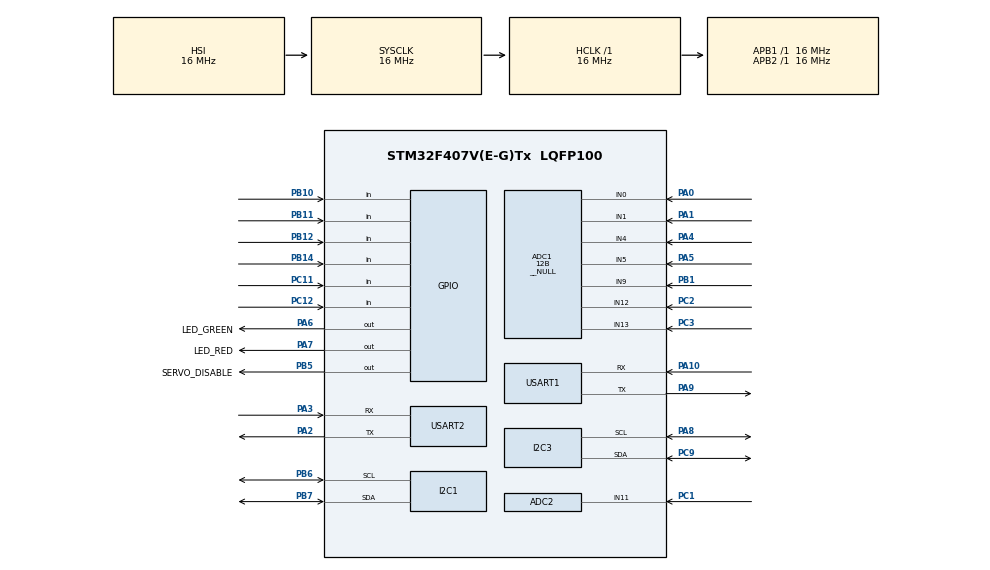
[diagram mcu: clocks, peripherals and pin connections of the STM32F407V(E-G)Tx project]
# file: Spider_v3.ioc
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ADC1.Channel-0\#ChannelRegularConversion=ADC_CHANNEL_13
ADC1.Channel-1\#ChannelRegularConversion=ADC_CHANNEL_12
ADC1.Channel-10\#ChannelRegularConversion=ADC_CHANNEL_9
ADC1.Channel-2\#ChannelRegularConversion=ADC_CHANNEL_1
ADC1.Channel-3\#ChannelRegularConversion=ADC_CHANNEL_0
ADC1.Channel-4\#ChannelRegularConversion=ADC_CHANNEL_0
ADC1.Channel-5\#ChannelRegularConversion=ADC_CHANNEL_0
ADC1.Channel-6\#ChannelRegularConversion=ADC_CHANNEL_0
ADC1.Channel-7\#ChannelRegularConversion=ADC_CHANNEL_0
ADC1.Channel-8\#ChannelRegularConversion=ADC_CHANNEL_5
ADC1.Channel-9\#ChannelRegularConversion=ADC_CHANNEL_4
ADC1.ClockPrescaler=ADC_CLOCK_SYNC_PCLK_DIV6
ADC1.ContinuousConvMode=ENABLE
ADC1.DMAContinuousRequests=ENABLE
ADC1.DataAlign=ADC_DATAALIGN_RIGHT
ADC1.DiscontinuousConvMode=DISABLE
ADC1.EOCSelection=ADC_EOC_SINGLE_CONV
ADC1.EnableAnalogWatchDog=false
ADC1.ExternalTrigConv=ADC_SOFTWARE_START
ADC1.ExternalTrigConvEdge=ADC_EXTERNALTRIGCONVEDGE_NONE
ADC1.InjNumberOfConversion=0
ADC1.Mode=__NULL
ADC1.NbrOfConversion=7
ADC1.NbrOfConversionFlag=1
ADC1.Rank-0\#ChannelRegularConversion=1
ADC1.Rank-1\#ChannelRegularConversion=2
ADC1.Rank-10\#ChannelRegularConversion=7
ADC1.Rank-2\#ChannelRegularConversion=3
ADC1.Rank-3\#ChannelRegularConversion=4
ADC1.Rank-4\#ChannelRegularConversion=5
ADC1.Rank-5\#ChannelRegularConversion=6
ADC1.Rank-6\#ChannelRegularConversion=7
ADC1.Rank-7\#ChannelRegularConversion=8
ADC1.Rank-8\#ChannelRegularConversion=5
ADC1.Rank-9\#ChannelRegularConversion=6
ADC1.Resolution=ADC_RESOLUTION_12B
ADC1.SamplingTime-0\#ChannelRegularConversion=ADC_SAMPLETIME_480CYCLES
ADC1.SamplingTime-1\#ChannelRegularConversion=ADC_SAMPLETIME_480CYCLES
ADC1.SamplingTime-10\#ChannelRegularConversion=ADC_SAMPLETIME_480CYCLES
ADC1.SamplingTime-2\#ChannelRegularConversion=ADC_SAMPLETIME_480CYCLES
ADC1.SamplingTime-3\#ChannelRegularConversion=ADC_SAMPLETIME_480CYCLES
ADC1.SamplingTime-4\#ChannelRegularConversion=ADC_SAMPLETIME_3CYCLES
ADC1.SamplingTime-5\#ChannelRegularConversion=ADC_SAMPLETIME_3CYCLES
ADC1.SamplingTime-6\#ChannelRegularConversion=ADC_SAMPLETIME_3CYCLES
ADC1.SamplingTime-7\#ChannelRegularConversion=ADC_SAMPLETIME_3CYCLES
ADC1.SamplingTime-8\#ChannelRegularConversion=ADC_SAMPLETIME_480CYCLES
ADC1.SamplingTime-9\#ChannelRegularConversion=ADC_SAMPLETIME_480CYCLES
ADC1.ScanConvMode=ENABLE
ADC1.master=1
ADC2.Channel-0\#ChannelRegularConversion=ADC_CHANNEL_11
ADC2.ClockPrescaler=ADC_CLOCK_SYNC_PCLK_DIV6
ADC2.NbrOfConversionFlag=1
ADC2.Rank-0\#ChannelRegularConversion=1
ADC2.SamplingTime-0\#ChannelRegularConversion=ADC_SAMPLETIME_28CYCLES
Dma.ADC1.0.Direction=DMA_PERIPH_TO_MEMORY
Dma.ADC1.0.FIFOMode=DMA_FIFOMODE_DISABLE
Dma.ADC1.0.Instance=DMA2_Stream0
Dma.ADC1.0.MemDataAlignment=DMA_MDATAALIGN_HALFWORD
Dma.ADC1.0.MemInc=DMA_MINC_ENABLE
Dma.ADC1.0.Mode=DMA_CIRCULAR
Dma.ADC1.0.PeriphDataAlignment=DMA_PDATAALIGN_HALFWORD
Dma.ADC1.0.PeriphInc=DMA_PINC_DISABLE
Dma.ADC1.0.Priority=DMA_PRIORITY_LOW
Dma.Request0=ADC1
FREERTOS.INCLUDE_vTaskDelayUntil=1
FREERTOS.Tasks01=defaultTask,0,128,StartDefaultTask,Default,NULL
I2C1.I2C_Mode=I2C_Standard
Mcu.Family=STM32F4
Mcu.Name=STM32F407V(E-G)Tx
Mcu.Package=LQFP100
NVIC.DMA2_Stream0_IRQn=true\:5\:0\:false\:false\:true\:true\:false
NVIC.PriorityGroup=NVIC_PRIORITYGROUP_4
NVIC.TIM2_IRQn=true\:0\:0\:false\:false\:true\:false\:false
NVIC.TimeBase=TIM2_IRQn
NVIC.TimeBaseIP=TIM2
NVIC.USART1_IRQn=true\:5\:0\:false\:false\:true\:true\:true
NVIC.USART2_IRQn=true\:5\:0\:false\:false\:true\:true\:true
PA0-WKUP.Signal=ADCx_IN0
PA1.Signal=ADCx_IN1
PA10.Mode=Asynchronous
PA10.Signal=USART1_RX
PA13.Mode=Serial_Wire
PA13.Signal=SYS_JTMS-SWDIO
PA14.Mode=Serial_Wire
PA14.Signal=SYS_JTCK-SWCLK
PA2.Mode=Asynchronous
PA2.Signal=USART2_TX
PA3.Mode=Asynchronous
PA3.Signal=USART2_RX
PA4.Signal=ADCx_IN4
PA5.Signal=ADCx_IN5
PA6.GPIO_Label=LED_GREEN
PA6.PinState=GPIO_PIN_SET
PA6.Signal=GPIO_Output
PA7.GPIO_Label=LED_RED
PA7.PinState=GPIO_PIN_SET
PA7.Signal=GPIO_Output
PA8.Mode=I2C
PA8.Signal=I2C3_SCL
PA9.Mode=Asynchronous
PA9.Signal=USART1_TX
PB1.Signal=ADCx_IN9
PB10.GPIO_PuPd=GPIO_PULLUP
PB10.Signal=GPIO_Input
PB11.GPIO_PuPd=GPIO_PULLUP
PB11.Signal=GPIO_Input
PB12.GPIO_PuPd=GPIO_PULLUP
PB12.Signal=GPIO_Input
PB14.GPIO_PuPd=GPIO_PULLUP
PB14.Signal=GPIO_Input
PB5.GPIO_Label=SERVO_DISABLE
PB5.PinState=GPIO_PIN_RESET
PB5.Signal=GPIO_Output
PB6.Mode=I2C
PB6.Signal=I2C1_SCL
PB7.Mode=I2C
PB7.Signal=I2C1_SDA
PC1.Signal=ADCx_IN11
PC11.GPIO_PuPd=GPIO_PULLUP
PC11.Signal=GPIO_Input
PC12.GPIO_PuPd=GPIO_PULLUP
PC12.Signal=GPIO_Input
PC2.Signal=ADCx_IN12
PC3.Signal=ADCx_IN13
PC9.Mode=I2C
PC9.Signal=I2C3_SDA
ProjectManager.HeapSize=0x200
ProjectManager.StackSize=0x400
ProjectManager.TargetToolchain=MDK-ARM V5
RCC.AHBFreq_Value=16000000
RCC.APB1Freq_Value=16000000
RCC.APB2Freq_Value=16000000
RCC.CortexFreq_Value=16000000
RCC.HSE_VALUE=25000000
RCC.HSI_VALUE=16000000
RCC.LSE_VALUE=32768
RCC.SYSCLKFreq_VALUE=16000000
RCC.VCOOutputFreq_Value=192000000
SH.ADCx_IN0.0=ADC1_IN0,IN0
SH.ADCx_IN1.0=ADC1_IN1,IN1
SH.ADCx_IN11.0=ADC2_IN11,IN11
SH.ADCx_IN12.0=ADC1_IN12,IN12
SH.ADCx_IN13.0=ADC1_IN13,IN13
SH.ADCx_IN4.0=ADC1_IN4,IN4
SH.ADCx_IN5.0=ADC1_IN5,IN5
SH.ADCx_IN9.0=ADC1_IN9,IN9
USART1.VirtualMode=VM_ASYNC
USART2.VirtualMode=VM_ASYNC
VP_FREERTOS_VS_ENABLE.Mode=Enabled
VP_SYS_VS_tim2.Mode=TIM2
board=Spider_v3

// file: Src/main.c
/**
  ******************************************************************************
  * File Name          : main.c
  * Description        : Main program body
  ******************************************************************************
  * This notice applies to any and all portions of this file
  * that are not between comment pairs USER CODE BEGIN and
  * USER CODE END. Other portions of this file, whether
  * inserted by the user or by software development tools
  * are owned by their respective copyright owners.
  *
  * Copyright (c) 2022 STMicroelectronics International N.V.
  * All rights reserved.
  *
  * Redistribution and use in source and binary forms, with or without
  * modification, are permitted, provided that the following conditions are met:
  *
  * 1. Redistribution of source code must retain the above copyright notice,
  *    this list of conditions and the following disclaimer.
  * 2. Redistributions in binary form must reproduce the above copyright notice,
  *    this list of conditions and the following disclaimer in the documentation
  *    and/or other materials provided with the distribution.
  * 3. Neither the name of STMicroelectronics nor the names of other
  *    contributors to this software may be used to endorse or promote products
  *    derived from this software without specific written permission.
  * 4. This software, including modifications and/or derivative works of this
  *    software, must execute solely and exclusively on microcontroller or
  *    microprocessor devices manufactured by or for STMicroelectronics.
  * 5. Redistribution and use of this software other than as permitted under
  *    this license is void and will automatically terminate your rights under
  *    this license.
  *
  * THIS SOFTWARE IS PROVIDED BY STMICROELECTRONICS AND CONTRIBUTORS "AS IS"
  * AND ANY EXPRESS, IMPLIED OR STATUTORY WARRANTIES, INCLUDING, BUT NOT
  * LIMITED TO, THE IMPLIED WARRANTIES OF MERCHANTABILITY, FITNESS FOR A
  * PARTICULAR PURPOSE AND NON-INFRINGEMENT OF THIRD PARTY INTELLECTUAL PROPERTY
  * RIGHTS ARE DISCLAIMED TO THE FULLEST EXTENT PERMITTED BY LAW. IN NO EVENT
  * SHALL STMICROELECTRONICS OR CONTRIBUTORS BE LIABLE FOR ANY DIRECT, INDIRECT,
  * INCIDENTAL, SPECIAL, EXEMPLARY, OR CONSEQUENTIAL DAMAGES (INCLUDING, BUT NOT
  * LIMITED TO, PROCUREMENT OF SUBSTITUTE GOODS OR SERVICES; LOSS OF USE, DATA,
  * OR PROFITS; OR BUSINESS INTERRUPTION) HOWEVER CAUSED AND ON ANY THEORY OF
  * LIABILITY, WHETHER IN CONTRACT, STRICT LIABILITY, OR TORT (INCLUDING
  * NEGLIGENCE OR OTHERWISE) ARISING IN ANY WAY OUT OF THE USE OF THIS SOFTWARE,
  * EVEN IF ADVISED OF THE POSSIBILITY OF SUCH DAMAGE.
  *
  ******************************************************************************
  */

#include "main.h"
#include "stm32f4xx_hal.h"
#include "cmsis_os.h"

/* USER CODE BEGIN Includes */
#include "spider_main.h"
/* USER CODE END Includes */

ADC_HandleTypeDef hadc1;
ADC_HandleTypeDef hadc2;
DMA_HandleTypeDef hdma_adc1;

I2C_HandleTypeDef hi2c1;
I2C_HandleTypeDef hi2c3;

UART_HandleTypeDef huart1;
UART_HandleTypeDef huart2;

osThreadId defaultTaskHandle;

/* USER CODE BEGIN PV */
/* Private variables ---------------------------------------------------------*/

/* USER CODE END PV */

void SystemClock_Config(void);
static void MX_GPIO_Init(void);
static void MX_DMA_Init(void);
static void MX_I2C1_Init(void);
static void MX_USART1_UART_Init(void);
static void MX_USART2_UART_Init(void);
static void MX_ADC1_Init(void);
static void MX_ADC2_Init(void);
static void MX_I2C3_Init(void);
void StartDefaultTask(void const * argument);

/* USER CODE BEGIN PFP */
/* Private function prototypes -----------------------------------------------*/

/* USER CODE END PFP */

int main(void)
{

  /* MCU Configuration----------------------------------------------------------*/

  /* Reset of all peripherals, Initializes the Flash interface and the Systick. */
  HAL_Init();

  /* Configure the system clock */
  SystemClock_Config();

  /* Initialize all configured peripherals */
  MX_GPIO_Init();
  MX_DMA_Init();
  MX_I2C1_Init();
  MX_USART1_UART_Init();
  MX_USART2_UART_Init();
  MX_ADC1_Init();
  MX_ADC2_Init();
  MX_I2C3_Init();

  /* USER CODE BEGIN 2 */
  post_init_handler();
  /* USER CODE END 2 */

  /* USER CODE BEGIN RTOS_TIMERS */
  /* start timers, add new ones, ... */
#ifdef USE_DEFAULT_TASK
  /* USER CODE END RTOS_TIMERS */

  /* Create the thread(s) */
  /* definition and creation of defaultTask */
  osThreadDef(defaultTask, StartDefaultTask, osPriorityNormal, 0, 128);
  defaultTaskHandle = osThreadCreate(osThread(defaultTask), NULL);

  /* USER CODE BEGIN RTOS_THREADS */
#endif
  /* add threads, ... */
  /* USER CODE END RTOS_THREADS */

  /* Start scheduler */
  osKernelStart();

  /* We should never get here as control is now taken by the scheduler */

  /* Infinite loop */
  while (1)
  {

  }

}

/** System Clock Configuration
*/
void SystemClock_Config(void)
{

  RCC_OscInitTypeDef RCC_OscInitStruct;
  RCC_ClkInitTypeDef RCC_ClkInitStruct;

    /**Configure the main internal regulator output voltage
    */
  __HAL_RCC_PWR_CLK_ENABLE();

  __HAL_PWR_VOLTAGESCALING_CONFIG(PWR_REGULATOR_VOLTAGE_SCALE1);

    /**Initializes the CPU, AHB and APB busses clocks
    */
  RCC_OscInitStruct.OscillatorType = RCC_OSCILLATORTYPE_HSI;
  RCC_OscInitStruct.HSIState = RCC_HSI_ON;
  RCC_OscInitStruct.HSICalibrationValue = 16;
  RCC_OscInitStruct.PLL.PLLState = RCC_PLL_NONE;
  if (HAL_RCC_OscConfig(&RCC_OscInitStruct) != HAL_OK)
  {
    _Error_Handler(__FILE__, __LINE__);
  }

    /**Initializes the CPU, AHB and APB busses clocks
    */
  RCC_ClkInitStruct.ClockType = RCC_CLOCKTYPE_HCLK|RCC_CLOCKTYPE_SYSCLK
                              |RCC_CLOCKTYPE_PCLK1|RCC_CLOCKTYPE_PCLK2;
  RCC_ClkInitStruct.SYSCLKSource = RCC_SYSCLKSOURCE_HSI;
  RCC_ClkInitStruct.AHBCLKDivider = RCC_SYSCLK_DIV1;
  RCC_ClkInitStruct.APB1CLKDivider = RCC_HCLK_DIV1;
  RCC_ClkInitStruct.APB2CLKDivider = RCC_HCLK_DIV1;

  if (HAL_RCC_ClockConfig(&RCC_ClkInitStruct, FLASH_LATENCY_0) != HAL_OK)
  {
    _Error_Handler(__FILE__, __LINE__);
  }

    /**Configure the Systick interrupt time
    */
  HAL_SYSTICK_Config(HAL_RCC_GetHCLKFreq()/1000);

    /**Configure the Systick
    */
  HAL_SYSTICK_CLKSourceConfig(SYSTICK_CLKSOURCE_HCLK);

  /* SysTick_IRQn interrupt configuration */
  HAL_NVIC_SetPriority(SysTick_IRQn, 15, 0);
}

/* ADC1 init function */
static void MX_ADC1_Init(void)
{

  ADC_ChannelConfTypeDef sConfig;

    /**Configure the global features of the ADC (Clock, Resolution, Data Alignment and number of conversion)
    */
  hadc1.Instance = ADC1;
  hadc1.Init.ClockPrescaler = ADC_CLOCK_SYNC_PCLK_DIV6;
  hadc1.Init.Resolution = ADC_RESOLUTION_12B;
  hadc1.Init.ScanConvMode = ENABLE;
  hadc1.Init.ContinuousConvMode = ENABLE;
  hadc1.Init.DiscontinuousConvMode = DISABLE;
  hadc1.Init.ExternalTrigConvEdge = ADC_EXTERNALTRIGCONVEDGE_NONE;
  hadc1.Init.ExternalTrigConv = ADC_SOFTWARE_START;
  hadc1.Init.DataAlign = ADC_DATAALIGN_RIGHT;
  hadc1.Init.NbrOfConversion = 7;
  hadc1.Init.DMAContinuousRequests = ENABLE;
  hadc1.Init.EOCSelection = ADC_EOC_SINGLE_CONV;
  if (HAL_ADC_Init(&hadc1) != HAL_OK)
  {
    _Error_Handler(__FILE__, __LINE__);
  }

    /**Configure for the selected ADC regular channel its corresponding rank in the sequencer and its sample time.
    */
  sConfig.Channel = ADC_CHANNEL_13;
  sConfig.Rank = 1;
  sConfig.SamplingTime = ADC_SAMPLETIME_480CYCLES;
  if (HAL_ADC_ConfigChannel(&hadc1, &sConfig) != HAL_OK)
  {
    _Error_Handler(__FILE__, __LINE__);
  }

    /**Configure for the selected ADC regular channel its corresponding rank in the sequencer and its sample time.
    */
  sConfig.Channel = ADC_CHANNEL_12;
  sConfig.Rank = 2;
  if (HAL_ADC_ConfigChannel(&hadc1, &sConfig) != HAL_OK)
  {
    _Error_Handler(__FILE__, __LINE__);
  }

    /**Configure for the selected ADC regular channel its corresponding rank in the sequencer and its sample time.
    */
  sConfig.Channel = ADC_CHANNEL_1;
  sConfig.Rank = 3;
  if (HAL_ADC_ConfigChannel(&hadc1, &sConfig) != HAL_OK)
  {
    _Error_Handler(__FILE__, __LINE__);
  }

    /**Configure for the selected ADC regular channel its corresponding rank in the sequencer and its sample time.
    */
  sConfig.Channel = ADC_CHANNEL_0;
  sConfig.Rank = 4;
  if (HAL_ADC_ConfigChannel(&hadc1, &sConfig) != HAL_OK)
  {
    _Error_Handler(__FILE__, __LINE__);
  }

    /**Configure for the selected ADC regular channel its corresponding rank in the sequencer and its sample time.
    */
  sConfig.Rank = 5;
  sConfig.SamplingTime = ADC_SAMPLETIME_3CYCLES;
  if (HAL_ADC_ConfigChannel(&hadc1, &sConfig) != HAL_OK)
  {
    _Error_Handler(__FILE__, __LINE__);
  }

    /**Configure for the selected ADC regular channel its corresponding rank in the sequencer and its sample time.
    */
  sConfig.Rank = 6;
  if (HAL_ADC_ConfigChannel(&hadc1, &sConfig) != HAL_OK)
  {
    _Error_Handler(__FILE__, __LINE__);
  }

    /**Configure for the selected ADC regular channel its corresponding rank in the sequencer and its sample time.
    */
  sConfig.Rank = 7;
  if (HAL_ADC_ConfigChannel(&hadc1, &sConfig) != HAL_OK)
  {
    _Error_Handler(__FILE__, __LINE__);
  }

    /**Configure for the selected ADC regular channel its corresponding rank in the sequencer and its sample time.
    */
  sConfig.Rank = 8;
  if (HAL_ADC_ConfigChannel(&hadc1, &sConfig) != HAL_OK)
  {
    _Error_Handler(__FILE__, __LINE__);
  }

    /**Configure for the selected ADC regular channel its corresponding rank in the sequencer and its sample time.
    */
  sConfig.Channel = ADC_CHANNEL_5;
  sConfig.Rank = 5;
  sConfig.SamplingTime = ADC_SAMPLETIME_480CYCLES;
  if (HAL_ADC_ConfigChannel(&hadc1, &sConfig) != HAL_OK)
  {
    _Error_Handler(__FILE__, __LINE__);
  }

    /**Configure for the selected ADC regular channel its corresponding rank in the sequencer and its sample time.
    */
  sConfig.Channel = ADC_CHANNEL_4;
  sConfig.Rank = 6;
  if (HAL_ADC_ConfigChannel(&hadc1, &sConfig) != HAL_OK)
  {
    _Error_Handler(__FILE__, __LINE__);
  }

    /**Configure for the selected ADC regular channel its corresponding rank in the sequencer and its sample time.
    */
  sConfig.Channel = ADC_CHANNEL_9;
  sConfig.Rank = 7;
  if (HAL_ADC_ConfigChannel(&hadc1, &sConfig) != HAL_OK)
  {
    _Error_Handler(__FILE__, __LINE__);
  }

}

/* ADC2 init function */
static void MX_ADC2_Init(void)
{

  ADC_ChannelConfTypeDef sConfig;

    /**Configure the global features of the ADC (Clock, Resolution, Data Alignment and number of conversion)
    */
  hadc2.Instance = ADC2;
  hadc2.Init.ClockPrescaler = ADC_CLOCK_SYNC_PCLK_DIV6;
  hadc2.Init.Resolution = ADC_RESOLUTION_12B;
  hadc2.Init.ScanConvMode = DISABLE;
  hadc2.Init.ContinuousConvMode = DISABLE;
  hadc2.Init.DiscontinuousConvMode = DISABLE;
  hadc2.Init.ExternalTrigConvEdge = ADC_EXTERNALTRIGCONVEDGE_NONE;
  hadc2.Init.ExternalTrigConv = ADC_SOFTWARE_START;
  hadc2.Init.DataAlign = ADC_DATAALIGN_RIGHT;
  hadc2.Init.NbrOfConversion = 1;
  hadc2.Init.DMAContinuousRequests = DISABLE;
  hadc2.Init.EOCSelection = ADC_EOC_SINGLE_CONV;
  if (HAL_ADC_Init(&hadc2) != HAL_OK)
  {
    _Error_Handler(__FILE__, __LINE__);
  }

    /**Configure for the selected ADC regular channel its corresponding rank in the sequencer and its sample time.
    */
  sConfig.Channel = ADC_CHANNEL_11;
  sConfig.Rank = 1;
  sConfig.SamplingTime = ADC_SAMPLETIME_28CYCLES;
  if (HAL_ADC_ConfigChannel(&hadc2, &sConfig) != HAL_OK)
  {
    _Error_Handler(__FILE__, __LINE__);
  }

}

/* I2C1 init function */
static void MX_I2C1_Init(void)
{

  hi2c1.Instance = I2C1;
  hi2c1.Init.ClockSpeed = 100000;
  hi2c1.Init.DutyCycle = I2C_DUTYCYCLE_2;
  hi2c1.Init.OwnAddress1 = 0;
  hi2c1.Init.AddressingMode = I2C_ADDRESSINGMODE_7BIT;
  hi2c1.Init.DualAddressMode = I2C_DUALADDRESS_DISABLE;
  hi2c1.Init.OwnAddress2 = 0;
  hi2c1.Init.GeneralCallMode = I2C_GENERALCALL_DISABLE;
  hi2c1.Init.NoStretchMode = I2C_NOSTRETCH_DISABLE;
  if (HAL_I2C_Init(&hi2c1) != HAL_OK)
  {
    _Error_Handler(__FILE__, __LINE__);
  }

}

/* I2C3 init function */
static void MX_I2C3_Init(void)
{

  hi2c3.Instance = I2C3;
  hi2c3.Init.ClockSpeed = 100000;
  hi2c3.Init.DutyCycle = I2C_DUTYCYCLE_2;
  hi2c3.Init.OwnAddress1 = 0;
  hi2c3.Init.AddressingMode = I2C_ADDRESSINGMODE_7BIT;
  hi2c3.Init.DualAddressMode = I2C_DUALADDRESS_DISABLE;
  hi2c3.Init.OwnAddress2 = 0;
  hi2c3.Init.GeneralCallMode = I2C_GENERALCALL_DISABLE;
  hi2c3.Init.NoStretchMode = I2C_NOSTRETCH_DISABLE;
  if (HAL_I2C_Init(&hi2c3) != HAL_OK)
  {
    _Error_Handler(__FILE__, __LINE__);
  }

}

/* USART1 init function */
static void MX_USART1_UART_Init(void)
{

  huart1.Instance = USART1;
  huart1.Init.BaudRate = 115200;
  huart1.Init.WordLength = UART_WORDLENGTH_8B;
  huart1.Init.StopBits = UART_STOPBITS_1;
  huart1.Init.Parity = UART_PARITY_NONE;
  huart1.Init.Mode = UART_MODE_TX_RX;
  huart1.Init.HwFlowCtl = UART_HWCONTROL_NONE;
  huart1.Init.OverSampling = UART_OVERSAMPLING_16;
  if (HAL_UART_Init(&huart1) != HAL_OK)
  {
    _Error_Handler(__FILE__, __LINE__);
  }

}

/* USART2 init function */
static void MX_USART2_UART_Init(void)
{

  huart2.Instance = USART2;
  huart2.Init.BaudRate = 115200;
  huart2.Init.WordLength = UART_WORDLENGTH_8B;
  huart2.Init.StopBits = UART_STOPBITS_1;
  huart2.Init.Parity = UART_PARITY_NONE;
  huart2.Init.Mode = UART_MODE_TX_RX;
  huart2.Init.HwFlowCtl = UART_HWCONTROL_NONE;
  huart2.Init.OverSampling = UART_OVERSAMPLING_16;
  if (HAL_UART_Init(&huart2) != HAL_OK)
  {
    _Error_Handler(__FILE__, __LINE__);
  }

}

static void MX_DMA_Init(void)
{
  /* DMA controller clock enable */
  __HAL_RCC_DMA2_CLK_ENABLE();

  /* DMA interrupt init */
  /* DMA2_Stream0_IRQn interrupt configuration */
  HAL_NVIC_SetPriority(DMA2_Stream0_IRQn, 5, 0);
  HAL_NVIC_EnableIRQ(DMA2_Stream0_IRQn);

}

/** Configure pins as
        * Analog
        * Input
        * Output
        * EVENT_OUT
        * EXTI
*/
static void MX_GPIO_Init(void)
{

  GPIO_InitTypeDef GPIO_InitStruct;

  /* GPIO Ports Clock Enable */
  __HAL_RCC_GPIOC_CLK_ENABLE();
  __HAL_RCC_GPIOA_CLK_ENABLE();
  __HAL_RCC_GPIOB_CLK_ENABLE();

  /*Configure GPIO pin Output Level */
  HAL_GPIO_WritePin(GPIOA, LED_GREEN_Pin|LED_RED_Pin, GPIO_PIN_SET);

  /*Configure GPIO pin Output Level */
  HAL_GPIO_WritePin(SERVO_DISABLE_GPIO_Port, SERVO_DISABLE_Pin, GPIO_PIN_RESET);

  /*Configure GPIO pins : LED_GREEN_Pin LED_RED_Pin */
  GPIO_InitStruct.Pin = LED_GREEN_Pin|LED_RED_Pin;
  GPIO_InitStruct.Mode = GPIO_MODE_OUTPUT_PP;
  GPIO_InitStruct.Pull = GPIO_NOPULL;
  GPIO_InitStruct.Speed = GPIO_SPEED_FREQ_LOW;
  HAL_GPIO_Init(GPIOA, &GPIO_InitStruct);

  /*Configure GPIO pins : PB10 PB11 PB12 PB14 */
  GPIO_InitStruct.Pin = GPIO_PIN_10|GPIO_PIN_11|GPIO_PIN_12|GPIO_PIN_14;
  GPIO_InitStruct.Mode = GPIO_MODE_INPUT;
  GPIO_InitStruct.Pull = GPIO_PULLUP;
  HAL_GPIO_Init(GPIOB, &GPIO_InitStruct);

  /*Configure GPIO pins : PC11 PC12 */
  GPIO_InitStruct.Pin = GPIO_PIN_11|GPIO_PIN_12;
  GPIO_InitStruct.Mode = GPIO_MODE_INPUT;
  GPIO_InitStruct.Pull = GPIO_PULLUP;
  HAL_GPIO_Init(GPIOC, &GPIO_InitStruct);

  /*Configure GPIO pin : SERVO_DISABLE_Pin */
  GPIO_InitStruct.Pin = SERVO_DISABLE_Pin;
  GPIO_InitStruct.Mode = GPIO_MODE_OUTPUT_PP;
  GPIO_InitStruct.Pull = GPIO_NOPULL;
  GPIO_InitStruct.Speed = GPIO_SPEED_FREQ_LOW;
  HAL_GPIO_Init(SERVO_DISABLE_GPIO_Port, &GPIO_InitStruct);

}

/* StartDefaultTask function */
void StartDefaultTask(void const * argument)
{

  for(;;)
  {
    osDelay(1);
  }
}

void HAL_TIM_PeriodElapsedCallback(TIM_HandleTypeDef *htim)
{
  if (htim->Instance == TIM2) {
    HAL_IncTick();
  }
}

void _Error_Handler(char * file, int line)
{
  while(1)
  {
  }
}

/************************ (C) COPYRIGHT STMicroelectronics *****END OF FILE****/
